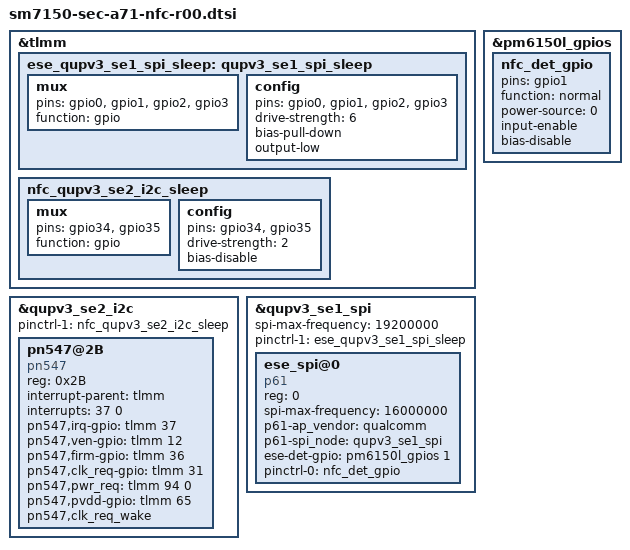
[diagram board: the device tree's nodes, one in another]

/* Copyright (c) 2016-2019, The Linux Foundation. All rights reserved.
 *
 * This program is free software; you can redistribute it and/or modify
 * it under the terms of the GNU General Public License version 2 and
 * only version 2 as published by the Free Software Foundation.
 *
 * This program is distributed in the hope that it will be useful,
 * but WITHOUT ANY WARRANTY; without even the implied warranty of
 * MERCHANTABILITY or FITNESS FOR A PARTICULAR PURPOSE.  See the
 * GNU General Public License for more details.
 */
/*
/ {
	aliases {
		spi2 = &qupv3_se1_spi;
	};
};
*/

&tlmm {
	ese_qupv3_se1_spi_sleep: qupv3_se1_spi_sleep {
		mux {
			pins = "gpio0", "gpio1", "gpio2",
						"gpio3";
			function = "gpio";
		};

		config {
			pins = "gpio0", "gpio1", "gpio2",
						"gpio3";
			drive-strength = <6>;
			bias-pull-down;
			output-low;
		};
	};

	nfc_qupv3_se2_i2c_sleep: nfc_qupv3_se2_i2c_sleep {
		mux {
			pins = "gpio34", "gpio35";
			function = "gpio";
		};
	
		config {
			pins = "gpio34", "gpio35";
			drive-strength = <2>;
			bias-disable;
		};
	};
};

&pm6150l_gpios {
	nfc_det_gpio: nfc_det_gpio {
		pins = "gpio1";
		function = "normal";
		power-source = <0>;
		input-enable;
		bias-disable;
	};
};

/* gpio34 and gpio35 are used for nfc i2c */
&qupv3_se2_i2c { 
	status = "okay";
	pinctrl-1 = <&nfc_qupv3_se2_i2c_sleep>;

	pn547@2B {
		compatible = "pn547";
		reg = <0x2B>;
		interrupt-parent = <&tlmm>;
		interrupts = <37 0>;
		pn547,irq-gpio = <&tlmm 37 0>;
		pn547,ven-gpio = <&tlmm 12 0>;
		pn547,firm-gpio = <&tlmm 36 0>;
		pn547,clk_req-gpio = <&tlmm 31 0>; /* BBCLK3 is controled by gpio 31 */
		pn547,pwr_req =  <&tlmm 94 0>;
		pn547,pvdd-gpio = <&tlmm 65 0>;
		/* pn547,nfc-det-gpio = <&pm6150l_gpios 1 0>; */ /* need to be checked */
		pn547,clk_req_wake;
	};
};

/* gpio 0~3 are used for ese spi */
&qupv3_se1_spi {
	status = "okay";
	spi-max-frequency = <19200000>;
	pinctrl-1 = <&ese_qupv3_se1_spi_sleep>;

	ese_spi@0 {
		compatible = "p61";
		reg = <0>;
		spi-max-frequency = <16000000>;
		p61-ap_vendor = "qualcomm";
		p61-spi_node = <&qupv3_se1_spi>;
		ese-det-gpio = <&pm6150l_gpios 1 0>; /* eSE_UICC_CHECK */
		pinctrl-names = "default";
		pinctrl-0 = <&nfc_det_gpio>;
	};
};
